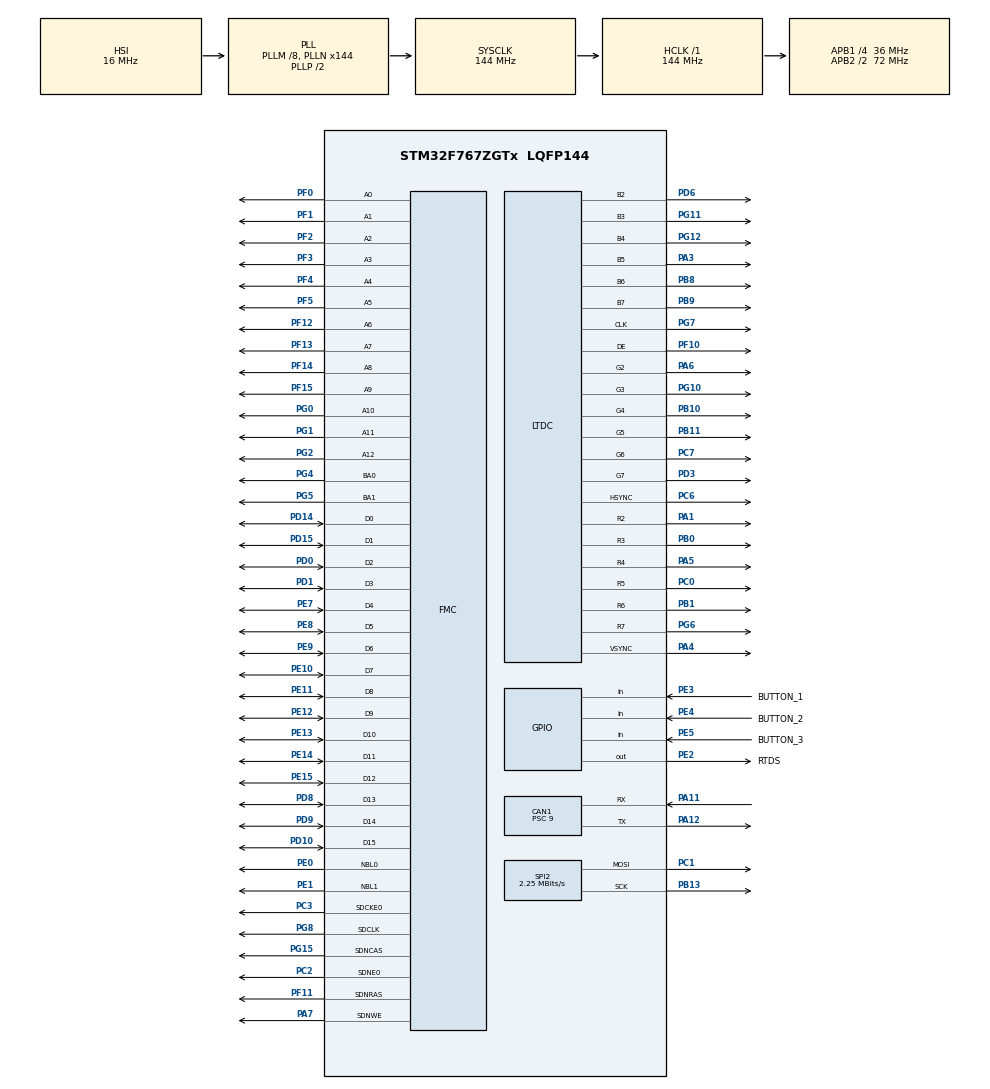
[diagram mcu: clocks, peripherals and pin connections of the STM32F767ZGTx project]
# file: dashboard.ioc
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CAN1.BS1=CAN_BS1_13TQ
CAN1.BS2=CAN_BS2_2TQ
CAN1.CalculateBaudRate=250000
CAN1.CalculateTimeBit=4000
CAN1.CalculateTimeQuantum=250.0
CAN1.NART=ENABLE
CAN1.Prescaler=9
FMC.CASLatency1=FMC_SDRAM_CAS_LATENCY_3
FMC.ColumnBitsNumber1=FMC_SDRAM_COLUMN_BITS_NUM_9
FMC.ExitSelfRefreshDelay1=8
FMC.LoadToActiveDelay1=2
FMC.RCDDelay1=2
FMC.RPDelay1=2
FMC.RPDelay2=2
FMC.ReadBurst1=FMC_SDRAM_RBURST_ENABLE
FMC.ReadBurst2=FMC_SDRAM_RBURST_ENABLE
FMC.ReadPipeDelay1=FMC_SDRAM_RPIPE_DELAY_1
FMC.ReadPipeDelay2=FMC_SDRAM_RPIPE_DELAY_1
FMC.RowCycleDelay1=7
FMC.RowCycleDelay2=7
FMC.SDClockPeriod1=FMC_SDRAM_CLOCK_PERIOD_2
FMC.SDClockPeriod2=FMC_SDRAM_CLOCK_PERIOD_2
FMC.SelfRefreshTime1=6
FMC.WriteRecoveryTime1=5
LTDC.ActiveH=272
LTDC.ActiveW=480
LTDC.Alpha0_L0=255
LTDC.Alpha0_L1=255
LTDC.Alpha_L0=255
LTDC.Alpha_L1=255
LTDC.BlendingFactor1_L0=LTDC_BLENDING_FACTOR1_CA
LTDC.Blue=0
LTDC.Blue_L0=255
LTDC.Blue_L1=255
LTDC.DEPolarity=LTDC_DEPOLARITY_AH
LTDC.FBStartAdress_L0=0xC0000000
LTDC.Green=0
LTDC.Green_L0=255
LTDC.Green_L1=255
LTDC.HBP=43
LTDC.HFP=8
LTDC.HSync=4
LTDC.ImageHeight_L0=272
LTDC.ImageWidth_L0=480
LTDC.Layers=0
LTDC.Red=0
LTDC.Red_L0=255
LTDC.Red_L1=255
LTDC.VBP=12
LTDC.VFP=8
LTDC.WindowX1_L0=480
LTDC.WindowX1_L1=480
LTDC.WindowY1_L0=272
LTDC.WindowY1_L1=272
Mcu.Family=STM32F7
Mcu.Name=STM32F767ZGTx
Mcu.Package=LQFP144
NVIC.CAN1_RX0_IRQn=true\:0\:0\:false\:false\:true\:true\:true\:true
NVIC.PriorityGroup=NVIC_PRIORITYGROUP_4
NVIC.TIM8_TRG_COM_TIM14_IRQn=true\:0\:0\:false\:false\:true\:true\:true\:true
NVIC.TIM8_UP_TIM13_IRQn=true\:0\:0\:false\:false\:true\:true\:true\:true
PA1.Mode=RGB666
PA1.Signal=LTDC_R2
PA11.Mode=CAN_Activate
PA11.Signal=CAN1_RX
PA12.Mode=CAN_Activate
PA12.Signal=CAN1_TX
PA13.Mode=Trace_Asynchronous_SW
PA13.Signal=SYS_JTMS-SWDIO
PA14.Mode=Trace_Asynchronous_SW
PA14.Signal=SYS_JTCK-SWCLK
PA3.Mode=RGB666
PA3.Signal=LTDC_B5
PA4.Mode=RGB666
PA4.Signal=LTDC_VSYNC
PA5.Mode=RGB666
PA5.Signal=LTDC_R4
PA6.Mode=RGB666
PA6.Signal=LTDC_G2
PA7.Signal=FMC_SDNWE
PB0.Mode=RGB666
PB0.Signal=LTDC_R3
PB1.Mode=RGB666
PB1.Signal=LTDC_R6
PB10.Mode=RGB666
PB10.Signal=LTDC_G4
PB11.Mode=RGB666
PB11.Signal=LTDC_G5
PB13.Mode=TX_Only_Simplex_Unidirect_Master
PB13.Signal=SPI2_SCK
PB3.Mode=Trace_Asynchronous_SW
PB3.Signal=SYS_JTDO-SWO
PB8.Mode=RGB666
PB8.Signal=LTDC_B6
PB9.Mode=RGB666
PB9.Signal=LTDC_B7
PC0.Mode=RGB666
PC0.Signal=LTDC_R5
PC1.Mode=TX_Only_Simplex_Unidirect_Master
PC1.Signal=SPI2_MOSI
PC2.Mode=SdramChipSelect1_1
PC2.Signal=FMC_SDNE0
PC3.Mode=SdramChipSelect1_1
PC3.Signal=FMC_SDCKE0
PC6.Mode=RGB666
PC6.Signal=LTDC_HSYNC
PC7.Mode=RGB666
PC7.Signal=LTDC_G6
PD0.Signal=FMC_D2_DA2
PD1.Signal=FMC_D3_DA3
PD10.Signal=FMC_D15_DA15
PD14.Signal=FMC_D0_DA0
PD15.Signal=FMC_D1_DA1
PD3.Mode=RGB666
PD3.Signal=LTDC_G7
PD6.Mode=RGB666
PD6.Signal=LTDC_B2
PD8.Signal=FMC_D13_DA13
PD9.Signal=FMC_D14_DA14
PE0.Signal=FMC_NBL0
PE1.Signal=FMC_NBL1
PE10.Signal=FMC_D7_DA7
PE11.Signal=FMC_D8_DA8
PE12.Signal=FMC_D9_DA9
PE13.Signal=FMC_D10_DA10
PE14.Signal=FMC_D11_DA11
PE15.Signal=FMC_D12_DA12
PE2.GPIO_Label=RTDS
PE2.Signal=GPIO_Output
PE3.GPIO_Label=BUTTON_1
PE3.GPIO_PuPd=GPIO_PULLDOWN
PE3.Signal=GPIO_Input
PE4.GPIO_Label=BUTTON_2
PE4.GPIO_PuPd=GPIO_PULLDOWN
PE4.Signal=GPIO_Input
PE5.GPIO_Label=BUTTON_3
PE5.GPIO_PuPd=GPIO_PULLDOWN
PE5.Signal=GPIO_Input
PE7.Signal=FMC_D4_DA4
PE8.Signal=FMC_D5_DA5
PE9.Signal=FMC_D6_DA6
PF0.Signal=FMC_A0
PF1.Signal=FMC_A1
PF10.Mode=RGB666
PF10.Signal=LTDC_DE
PF11.Signal=FMC_SDNRAS
PF12.Signal=FMC_A6
PF13.Signal=FMC_A7
PF14.Signal=FMC_A8
PF15.Signal=FMC_A9
PF2.Signal=FMC_A2
PF3.Signal=FMC_A3
PF4.Signal=FMC_A4
PF5.Signal=FMC_A5
PG0.Signal=FMC_A10
PG1.Signal=FMC_A11
PG10.Mode=RGB666
PG10.Signal=LTDC_G3
PG11.Mode=RGB666
PG11.Signal=LTDC_B3
PG12.Mode=RGB666
PG12.Signal=LTDC_B4
PG15.Signal=FMC_SDNCAS
PG2.Signal=FMC_A12
PG4.Signal=FMC_A14_BA0
PG5.Signal=FMC_A15_BA1
PG6.Mode=RGB666
PG6.Signal=LTDC_R7
PG7.Mode=RGB666
PG7.Signal=LTDC_CLK
PG8.Signal=FMC_SDCLK
ProjectManager.HeapSize=0x200
ProjectManager.StackSize=0x400
ProjectManager.TargetToolchain=STM32CubeIDE
RCC.AHBFreq_Value=144000000
RCC.APB1CLKDivider=RCC_HCLK_DIV4
RCC.APB1Freq_Value=36000000
RCC.APB1TimFreq_Value=72000000
RCC.APB2CLKDivider=RCC_HCLK_DIV2
RCC.APB2Freq_Value=72000000
RCC.APB2TimFreq_Value=144000000
RCC.CortexFreq_Value=144000000
RCC.HCLKFreq_Value=144000000
RCC.HSE_VALUE=25000000
RCC.HSI_VALUE=16000000
RCC.LSE_VALUE=32768
RCC.PLLM=8
RCC.PLLN=144
RCC.PLLSAIN=100
RCC.PLLSAIR=5
RCC.SYSCLKFreq_VALUE=144000000
RCC.SYSCLKSource=RCC_SYSCLKSOURCE_PLLCLK
RCC.USBFreq_Value=144000000
RCC.VCOOutputFreq_Value=288000000
SH.FMC_A0.0=FMC_A0,13b-sda1
SH.FMC_A1.0=FMC_A1,13b-sda1
SH.FMC_A10.0=FMC_A10,13b-sda1
SH.FMC_A11.0=FMC_A11,13b-sda1
SH.FMC_A12.0=FMC_A12,13b-sda1
SH.FMC_A14_BA0.0=FMC_BA0,FourSdramBanks1
SH.FMC_A15_BA1.0=FMC_BA1,FourSdramBanks1
SH.FMC_A2.0=FMC_A2,13b-sda1
SH.FMC_A3.0=FMC_A3,13b-sda1
SH.FMC_A4.0=FMC_A4,13b-sda1
SH.FMC_A5.0=FMC_A5,13b-sda1
SH.FMC_A6.0=FMC_A6,13b-sda1
SH.FMC_A7.0=FMC_A7,13b-sda1
SH.FMC_A8.0=FMC_A8,13b-sda1
SH.FMC_A9.0=FMC_A9,13b-sda1
SH.FMC_D0_DA0.0=FMC_D0,sd-16b-d1
SH.FMC_D10_DA10.0=FMC_D10,sd-16b-d1
SH.FMC_D11_DA11.0=FMC_D11,sd-16b-d1
SH.FMC_D12_DA12.0=FMC_D12,sd-16b-d1
SH.FMC_D13_DA13.0=FMC_D13,sd-16b-d1
SH.FMC_D14_DA14.0=FMC_D14,sd-16b-d1
SH.FMC_D15_DA15.0=FMC_D15,sd-16b-d1
SH.FMC_D1_DA1.0=FMC_D1,sd-16b-d1
SH.FMC_D2_DA2.0=FMC_D2,sd-16b-d1
SH.FMC_D3_DA3.0=FMC_D3,sd-16b-d1
SH.FMC_D4_DA4.0=FMC_D4,sd-16b-d1
SH.FMC_D5_DA5.0=FMC_D5,sd-16b-d1
SH.FMC_D6_DA6.0=FMC_D6,sd-16b-d1
SH.FMC_D7_DA7.0=FMC_D7,sd-16b-d1
SH.FMC_D8_DA8.0=FMC_D8,sd-16b-d1
SH.FMC_D9_DA9.0=FMC_D9,sd-16b-d1
SH.FMC_NBL0.0=FMC_NBL0,Sd2ByteEnable1
SH.FMC_NBL1.0=FMC_NBL1,Sd2ByteEnable1
SH.FMC_SDCLK.0=FMC_SDCLK,13b-sda1
SH.FMC_SDNCAS.0=FMC_SDNCAS,13b-sda1
SH.FMC_SDNRAS.0=FMC_SDNRAS,13b-sda1
SH.FMC_SDNWE.0=FMC_SDNWE,13b-sda1
SPI2.BaudRatePrescaler=SPI_BAUDRATEPRESCALER_16
SPI2.CalculateBaudRate=2.25 MBits/s
SPI2.DataSize=SPI_DATASIZE_8BIT
SPI2.Direction=SPI_DIRECTION_2LINES
SPI2.Mode=SPI_MODE_MASTER
SPI2.VirtualType=VM_MASTER
TIM13.Prescaler=105
TIM14.Prescaler=100
VP_TIM13_VS_ClockSourceINT.Mode=Enable_Timer
VP_TIM14_VS_ClockSourceINT.Mode=Enable_Timer
board=custom

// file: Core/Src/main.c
/* USER CODE BEGIN Header */
/**
  ******************************************************************************
  * @file           : main.c
  * @brief          : Main program body
  ******************************************************************************
  * @attention
  *
  * Copyright (c) 2023 STMicroelectronics.
  * All rights reserved.
  *
  * This software is licensed under terms that can be found in the LICENSE file
  * in the root directory of this software component.
  * If no LICENSE file comes with this software, it is provided AS-IS.
  *
  ******************************************************************************
  */
/* USER CODE END Header */
#include "main.h"
#include "can.h"
#include "ltdc.h"
#include "spi.h"
#include "tim.h"
#include "gpio.h"
#include "fmc.h"

/* USER CODE BEGIN Includes */
#include "led.h"
#include "vehicle.h"
#include "sdram_defines.h"
#include <stdlib.h>
#include <string.h>
#include <lvgl.h>
#include "screens.h"
#include "dash_error.h"
#include "morse.h"
/* USER CODE END Includes */

/* USER CODE BEGIN PTD */
// Global vehicle
volatile Vehicle_Data the_vehicle = {0};
volatile enum DASH_ERROR_TYPE current_error = CAN_ERROR;
/* USER CODE END PTD */

void SystemClock_Config(void);

int main(void)
{

  /* MCU Configuration--------------------------------------------------------*/

  /* Reset of all peripherals, Initializes the Flash interface and the Systick. */
  HAL_Init();

  /* Configure the system clock */
  SystemClock_Config();

  /* Initialize all configured peripherals */
  MX_GPIO_Init();
  MX_FMC_Init();
  MX_LTDC_Init();
  MX_SPI2_Init();
  MX_TIM14_Init();
  MX_TIM13_Init();
  MX_CAN1_Init();
  /* USER CODE BEGIN 2 */
    // LED Initializations
    init_led();
    set_all_red();

    SDRAM_Init(&hsdram1);
    HAL_Delay(10);

    // Initialize the driver
    init_displays();
    init_screens();
    change_screens(DRIVER_SCREEN);
    disable_popups();
    HAL_TIM_Base_Start_IT(&htim14);

  /* USER CODE END 2 */

  /* Infinite loop */
    while (1) {

    /* USER CODE BEGIN 3 */
        lv_timer_handler();

        try_update_screen();
        try_cycle_screens();
        try_enable_popups();
        try_disable_popups();
        try_change_screens();

        HAL_Delay(2);

    }
  /* USER CODE END 3 */
}

void SystemClock_Config(void)
{
  RCC_OscInitTypeDef RCC_OscInitStruct = {0};
  RCC_ClkInitTypeDef RCC_ClkInitStruct = {0};

  /** Configure the main internal regulator output voltage
  */
  __HAL_RCC_PWR_CLK_ENABLE();
  __HAL_PWR_VOLTAGESCALING_CONFIG(PWR_REGULATOR_VOLTAGE_SCALE3);

  /** Initializes the RCC Oscillators according to the specified parameters
  * in the RCC_OscInitTypeDef structure.
  */
  RCC_OscInitStruct.OscillatorType = RCC_OSCILLATORTYPE_HSI;
  RCC_OscInitStruct.HSIState = RCC_HSI_ON;
  RCC_OscInitStruct.HSICalibrationValue = RCC_HSICALIBRATION_DEFAULT;
  RCC_OscInitStruct.PLL.PLLState = RCC_PLL_ON;
  RCC_OscInitStruct.PLL.PLLSource = RCC_PLLSOURCE_HSI;
  RCC_OscInitStruct.PLL.PLLM = 8;
  RCC_OscInitStruct.PLL.PLLN = 144;
  RCC_OscInitStruct.PLL.PLLP = RCC_PLLP_DIV2;
  RCC_OscInitStruct.PLL.PLLQ = 2;
  RCC_OscInitStruct.PLL.PLLR = 2;
  if (HAL_RCC_OscConfig(&RCC_OscInitStruct) != HAL_OK)
  {
    Error_Handler();
  }

  /** Initializes the CPU, AHB and APB buses clocks
  */
  RCC_ClkInitStruct.ClockType = RCC_CLOCKTYPE_HCLK|RCC_CLOCKTYPE_SYSCLK
                              |RCC_CLOCKTYPE_PCLK1|RCC_CLOCKTYPE_PCLK2;
  RCC_ClkInitStruct.SYSCLKSource = RCC_SYSCLKSOURCE_PLLCLK;
  RCC_ClkInitStruct.AHBCLKDivider = RCC_SYSCLK_DIV1;
  RCC_ClkInitStruct.APB1CLKDivider = RCC_HCLK_DIV4;
  RCC_ClkInitStruct.APB2CLKDivider = RCC_HCLK_DIV2;

  if (HAL_RCC_ClockConfig(&RCC_ClkInitStruct, FLASH_LATENCY_4) != HAL_OK)
  {
    Error_Handler();
  }
}

void Error_Handler(void)
{
  /* USER CODE BEGIN Error_Handler_Debug */
    /* User can add his own implementation to report the HAL error return state */
    if (current_error == CAN_ERROR) {
        HAL_CAN_DeInit(&hcan1);
        MX_CAN1_Init();
        return;
    }
    __disable_irq();
    while (1) {
    }
  /* USER CODE END Error_Handler_Debug */
}
